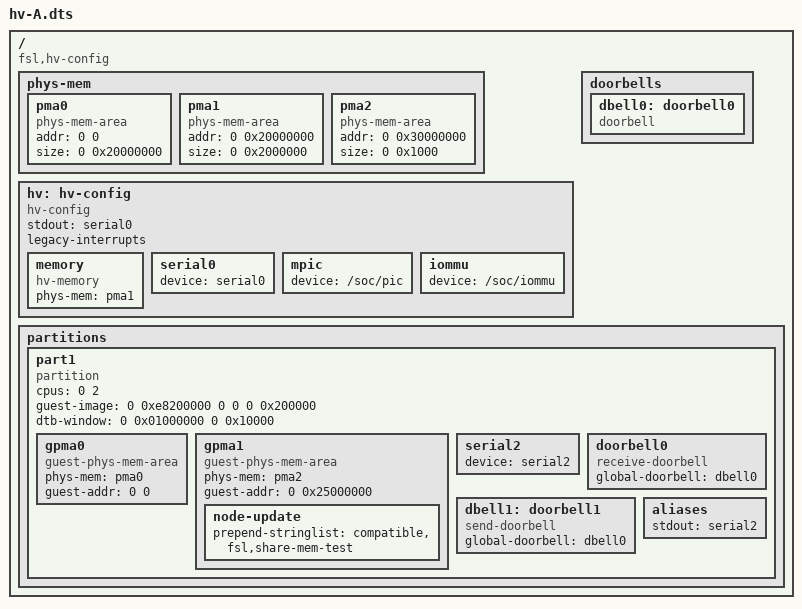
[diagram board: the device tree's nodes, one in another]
/dts-v1/;

/ {
	compatible = "fsl,hv-config";

	phys-mem {
		pma0: pma0 {
			compatible = "phys-mem-area";
			addr = <0 0>;
			size = <0 0x20000000>;
		};

		pma1: pma1 {
			compatible = "phys-mem-area";
			addr = <0 0x20000000>;
			size = <0 0x2000000>;
		};

		pma2: pma2 {
			compatible = "phys-mem-area";
			addr = <0 0x30000000>;
			size = <0 0x1000>;
		};
	};

	hv: hv-config {
		compatible = "hv-config";
		stdout = <&serial0>;
		legacy-interrupts;

		memory {
			compatible = "hv-memory";
			phys-mem = <&pma1>;
		};

		serial0: serial0 {
			// Hypervisor console
			device = "serial0";
		};

		mpic {
			device = "/soc/pic";
		};

		iommu {
			device = "/soc/iommu";
		};
	};

	doorbells {
		dbell0: doorbell0 {
			compatible = "doorbell";
		};
	};

	partitions {
		part1 {
			compatible = "partition";
			cpus = <0 2>;
			guest-image = <0 0xe8200000 0 0 0 0x200000>;
			dtb-window = <0 0x01000000 0 0x10000>;

			gpma0 {
				compatible = "guest-phys-mem-area";
				phys-mem = <&pma0>;
				guest-addr = <0 0>;
			};

			gpma1 {
				compatible = "guest-phys-mem-area";
				phys-mem = <&pma2>;
				guest-addr = <0 0x25000000>;
				node-update {
					prepend-stringlist = "compatible", "fsl,share-mem-test";
				};
			};

			serial2: serial2 {
				device = "serial2";
			};

			doorbell0 {
				compatible = "receive-doorbell";
				global-doorbell = <&dbell0>;
			};

			dbell1: doorbell1 {
				compatible = "send-doorbell";
				global-doorbell = <&dbell0>;
			};

			aliases {
				stdout = <&serial2>;
			};
		};
	};
};
